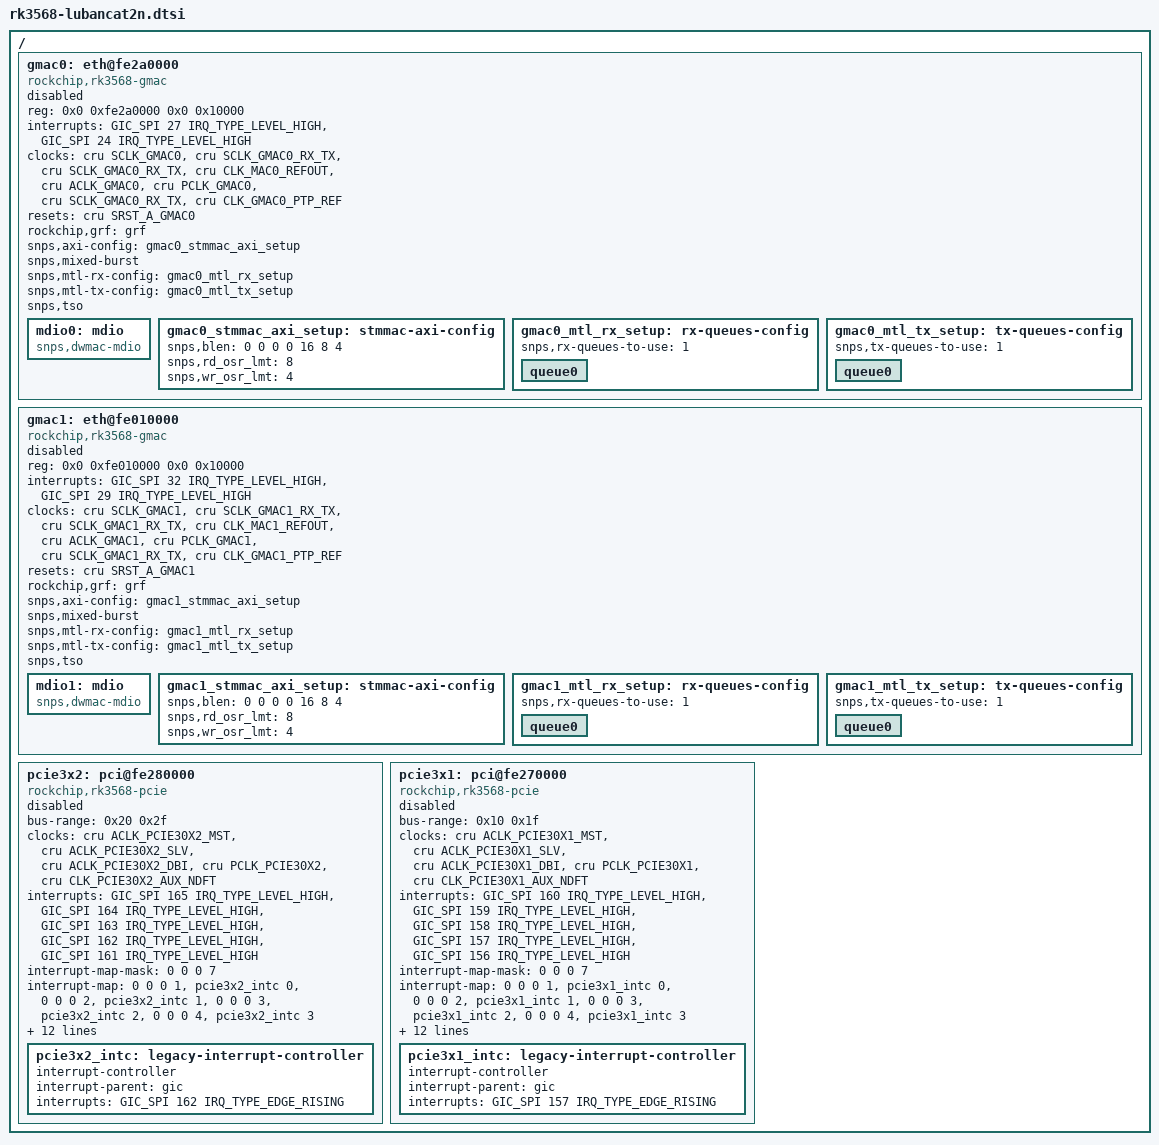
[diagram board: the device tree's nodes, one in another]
// SPDX-License-Identifier: (GPL-2.0+ OR MIT)
/*
* Copyright (c) 2021 Rockchip Electronics Co., Ltd.
* Copyright (c) 2022 EmbedFire <embedfire@embedfire.com>
*/

/dts-v1/;
#include <dt-bindings/gpio/gpio.h>
#include <dt-bindings/leds/common.h>
#include <dt-bindings/pinctrl/rockchip.h>
#include <dt-bindings/soc/rockchip,vop2.h>
#include "rk3568.dtsi"

/delete-node/ &gmac0;
/delete-node/ &gmac1;
/delete-node/ &pcie3x1;
/delete-node/ &pcie3x2;

/ {
	gmac0: eth@fe2a0000 {
		compatible = "rockchip,rk3568-gmac", "snps,dwmac-4.20a";
		reg = <0x0 0xfe2a0000 0x0 0x10000>;
		interrupts = <GIC_SPI 27 IRQ_TYPE_LEVEL_HIGH>,
			     <GIC_SPI 24 IRQ_TYPE_LEVEL_HIGH>;
		interrupt-names = "macirq", "eth_wake_irq";
		clocks = <&cru SCLK_GMAC0>, <&cru SCLK_GMAC0_RX_TX>,
			 <&cru SCLK_GMAC0_RX_TX>, <&cru CLK_MAC0_REFOUT>,
			 <&cru ACLK_GMAC0>, <&cru PCLK_GMAC0>,
			 <&cru SCLK_GMAC0_RX_TX>, <&cru CLK_GMAC0_PTP_REF>;
		clock-names = "stmmaceth", "mac_clk_rx",
			      "mac_clk_tx", "clk_mac_refout",
			      "aclk_mac", "pclk_mac",
			      "clk_mac_speed", "ptp_ref";
		resets = <&cru SRST_A_GMAC0>;
		reset-names = "stmmaceth";
		rockchip,grf = <&grf>;
		snps,axi-config = <&gmac0_stmmac_axi_setup>;
		snps,mixed-burst;
		snps,mtl-rx-config = <&gmac0_mtl_rx_setup>;
		snps,mtl-tx-config = <&gmac0_mtl_tx_setup>;
		snps,tso;
		status = "disabled";

		mdio0: mdio {
			compatible = "snps,dwmac-mdio";
			#address-cells = <0x1>;
			#size-cells = <0x0>;
		};

		gmac0_stmmac_axi_setup: stmmac-axi-config {
			snps,blen = <0 0 0 0 16 8 4>;
			snps,rd_osr_lmt = <8>;
			snps,wr_osr_lmt = <4>;
		};

		gmac0_mtl_rx_setup: rx-queues-config {
			snps,rx-queues-to-use = <1>;
			queue0 {};
		};

		gmac0_mtl_tx_setup: tx-queues-config {
			snps,tx-queues-to-use = <1>;
			queue0 {};
		};
	};

	gmac1: eth@fe010000 {
		compatible = "rockchip,rk3568-gmac", "snps,dwmac-4.20a";
		reg = <0x0 0xfe010000 0x0 0x10000>;
		interrupts = <GIC_SPI 32 IRQ_TYPE_LEVEL_HIGH>,
			     <GIC_SPI 29 IRQ_TYPE_LEVEL_HIGH>;
		interrupt-names = "macirq", "eth_wake_irq";
		clocks = <&cru SCLK_GMAC1>, <&cru SCLK_GMAC1_RX_TX>,
			 <&cru SCLK_GMAC1_RX_TX>, <&cru CLK_MAC1_REFOUT>,
			 <&cru ACLK_GMAC1>, <&cru PCLK_GMAC1>,
			 <&cru SCLK_GMAC1_RX_TX>, <&cru CLK_GMAC1_PTP_REF>;
		clock-names = "stmmaceth", "mac_clk_rx",
			      "mac_clk_tx", "clk_mac_refout",
			      "aclk_mac", "pclk_mac",
			      "clk_mac_speed", "ptp_ref";
		resets = <&cru SRST_A_GMAC1>;
		reset-names = "stmmaceth";
		rockchip,grf = <&grf>;
		snps,axi-config = <&gmac1_stmmac_axi_setup>;
		snps,mixed-burst;
		snps,mtl-rx-config = <&gmac1_mtl_rx_setup>;
		snps,mtl-tx-config = <&gmac1_mtl_tx_setup>;
		snps,tso;
		status = "disabled";

		mdio1: mdio {
			compatible = "snps,dwmac-mdio";
			#address-cells = <0x1>;
			#size-cells = <0x0>;
		};

		gmac1_stmmac_axi_setup: stmmac-axi-config {
			snps,blen = <0 0 0 0 16 8 4>;
			snps,rd_osr_lmt = <8>;
			snps,wr_osr_lmt = <4>;
		};

		gmac1_mtl_rx_setup: rx-queues-config {
			snps,rx-queues-to-use = <1>;
			queue0 {};
		};

		gmac1_mtl_tx_setup: tx-queues-config {
			snps,tx-queues-to-use = <1>;
			queue0 {};
		};
	};

	pcie3x2: pci@fe280000 {
		compatible = "rockchip,rk3568-pcie";
		#address-cells = <3>;
		#size-cells = <2>;
		bus-range = <0x20 0x2f>;
		clocks = <&cru ACLK_PCIE30X2_MST>, <&cru ACLK_PCIE30X2_SLV>,
			 <&cru ACLK_PCIE30X2_DBI>, <&cru PCLK_PCIE30X2>,
			 <&cru CLK_PCIE30X2_AUX_NDFT>;
		clock-names = "aclk_mst", "aclk_slv",
			      "aclk_dbi", "pclk", "aux";
		device_type = "pci";
		interrupts = <GIC_SPI 165 IRQ_TYPE_LEVEL_HIGH>,
			     <GIC_SPI 164 IRQ_TYPE_LEVEL_HIGH>,
			     <GIC_SPI 163 IRQ_TYPE_LEVEL_HIGH>,
			     <GIC_SPI 162 IRQ_TYPE_LEVEL_HIGH>,
			     <GIC_SPI 161 IRQ_TYPE_LEVEL_HIGH>;
		interrupt-names = "sys", "pmc", "msg", "legacy", "err";
		#interrupt-cells = <1>;
		interrupt-map-mask = <0 0 0 7>;
		interrupt-map = <0 0 0 1 &pcie3x2_intc 0>,
				<0 0 0 2 &pcie3x2_intc 1>,
				<0 0 0 3 &pcie3x2_intc 2>,
				<0 0 0 4 &pcie3x2_intc 3>;
		linux,pci-domain = <2>;
		num-ib-windows = <6>;
		num-ob-windows = <2>;
		max-link-speed = <3>;
		msi-map = <0x2000 &its 0x2000 0x1000>;
		num-lanes = <2>;
		phys = <&pcie30phy>;
		phy-names = "pcie-phy";
		power-domains = <&power RK3568_PD_PIPE>;
		reg = <0x3 0xc0800000 0x0 0x00400000>,
		      <0x0 0xfe280000 0x0 0x00010000>,
		      <0x3 0xbf000000 0x0 0x01000000>;
		ranges = <0x01000000 0x0 0x3ef00000 0x3 0xbef00000 0x0 0x00100000>,
			 <0x02000000 0x0 0x00000000 0x3 0x80000000 0x0 0x3ef00000>;
		reg-names = "dbi", "apb", "config";
		resets = <&cru SRST_PCIE30X2_POWERUP>;
		reset-names = "pipe";
		/* bifurcation; lane0 when using 1+1 */
		status = "disabled";

		pcie3x2_intc: legacy-interrupt-controller {
			interrupt-controller;
			#address-cells = <0>;
			#interrupt-cells = <1>;
			interrupt-parent = <&gic>;
			interrupts = <GIC_SPI 162 IRQ_TYPE_EDGE_RISING>;
		};
	};

	pcie3x1: pci@fe270000 {
		compatible = "rockchip,rk3568-pcie";
		#address-cells = <3>;
		#size-cells = <2>;
		bus-range = <0x10 0x1f>;
		clocks = <&cru ACLK_PCIE30X1_MST>, <&cru ACLK_PCIE30X1_SLV>,
			 <&cru ACLK_PCIE30X1_DBI>, <&cru PCLK_PCIE30X1>,
			 <&cru CLK_PCIE30X1_AUX_NDFT>;
		clock-names = "aclk_mst", "aclk_slv",
			      "aclk_dbi", "pclk", "aux";
		device_type = "pci";
		interrupts = <GIC_SPI 160 IRQ_TYPE_LEVEL_HIGH>,
			     <GIC_SPI 159 IRQ_TYPE_LEVEL_HIGH>,
			     <GIC_SPI 158 IRQ_TYPE_LEVEL_HIGH>,
			     <GIC_SPI 157 IRQ_TYPE_LEVEL_HIGH>,
			     <GIC_SPI 156 IRQ_TYPE_LEVEL_HIGH>;
		interrupt-names = "sys", "pmc", "msg", "legacy", "err";
		#interrupt-cells = <1>;
		interrupt-map-mask = <0 0 0 7>;
		interrupt-map = <0 0 0 1 &pcie3x1_intc 0>,
				<0 0 0 2 &pcie3x1_intc 1>,
				<0 0 0 3 &pcie3x1_intc 2>,
				<0 0 0 4 &pcie3x1_intc 3>;
		linux,pci-domain = <1>;
		num-ib-windows = <6>;
		num-ob-windows = <2>;
		max-link-speed = <3>;
		msi-map = <0x1000 &its 0x1000 0x1000>;
		num-lanes = <1>;
		phys = <&pcie30phy>;
		phy-names = "pcie-phy";
		power-domains = <&power RK3568_PD_PIPE>;
		reg = <0x3 0xc0400000 0x0 0x00400000>,
		      <0x0 0xfe270000 0x0 0x00010000>,
		      <0x3 0x7f000000 0x0 0x01000000>;
		ranges = <0x01000000 0x0 0x3ef00000 0x3 0x7ef00000 0x0 0x00100000>,
			 <0x02000000 0x0 0x00000000 0x3 0x40000000 0x0 0x3ef00000>;
		reg-names = "dbi", "apb", "config";
		resets = <&cru SRST_PCIE30X1_POWERUP>;
		reset-names = "pipe";
		/* bifurcation; lane1 when using 1+1 */
		status = "disabled";

		pcie3x1_intc: legacy-interrupt-controller {
			interrupt-controller;
			#address-cells = <0>;
			#interrupt-cells = <1>;
			interrupt-parent = <&gic>;
			interrupts = <GIC_SPI 157 IRQ_TYPE_EDGE_RISING>;
		};
	};
};
